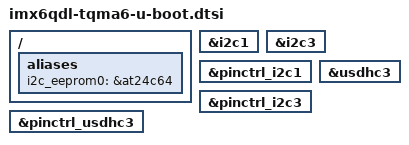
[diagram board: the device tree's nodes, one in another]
// SPDX-License-Identifier: (GPL-2.0-or-later OR MIT)
/*
 * Copyright (c) 2023 TQ-Systems GmbH <u-boot@ew.tq-group.com>,
 * D-82229 Seefeld, Germany.
 * Author: Markus Niebel
 */

/* SOC specific U-Boot DT adjustments */

#include "imx6qdl-u-boot.dtsi"

/ {
	aliases {
		i2c_eeprom0 = &at24c64;
	};
};

&i2c1 {
	u-boot,dm-spl;
};

&i2c3 {
	u-boot,dm-spl;
};

&pinctrl_i2c1 {
	u-boot,dm-spl;
};

&pinctrl_i2c3 {
	u-boot,dm-spl;
};

&pinctrl_usdhc3 {
	u-boot,dm-spl;
};

&usdhc3 {
	u-boot,dm-spl;
};
